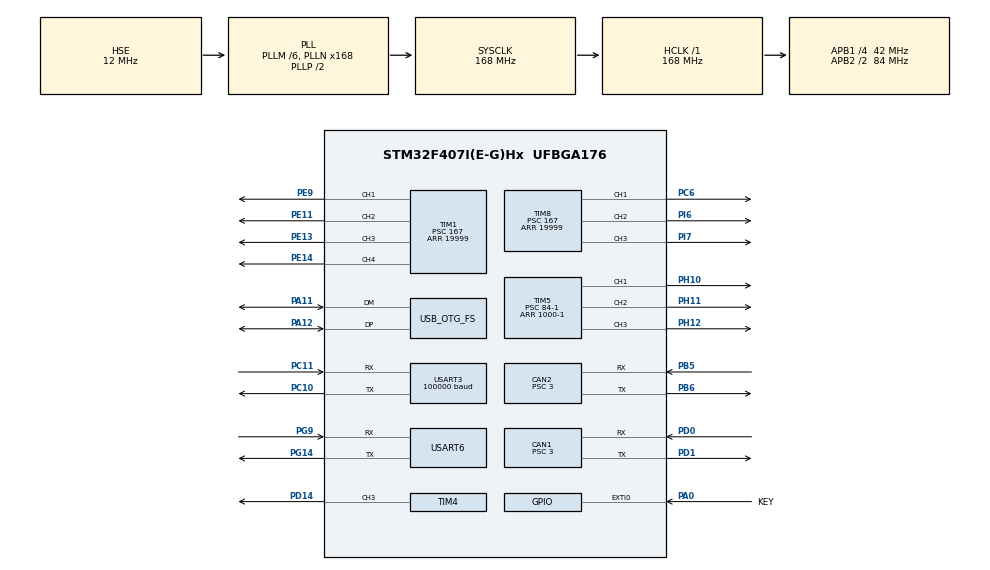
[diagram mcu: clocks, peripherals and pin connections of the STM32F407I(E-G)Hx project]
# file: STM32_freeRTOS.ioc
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CAN1.BS1=CAN_BS1_10TQ
CAN1.BS2=CAN_BS2_3TQ
CAN1.CalculateBaudRate=1000000
CAN1.CalculateTimeBit=1000
CAN1.CalculateTimeQuantum=71.42857142857143
CAN1.Prescaler=3
CAN2.BS1=CAN_BS1_10TQ
CAN2.BS2=CAN_BS2_3TQ
CAN2.CalculateBaudRate=1000000
CAN2.CalculateTimeBit=1000
CAN2.CalculateTimeQuantum=71.42857142857143
CAN2.Prescaler=3
Dma.Request0=USART3_RX
Dma.USART3_RX.0.Direction=DMA_PERIPH_TO_MEMORY
Dma.USART3_RX.0.FIFOMode=DMA_FIFOMODE_DISABLE
Dma.USART3_RX.0.Instance=DMA1_Stream1
Dma.USART3_RX.0.MemDataAlignment=DMA_MDATAALIGN_BYTE
Dma.USART3_RX.0.MemInc=DMA_MINC_ENABLE
Dma.USART3_RX.0.Mode=DMA_NORMAL
Dma.USART3_RX.0.PeriphDataAlignment=DMA_PDATAALIGN_BYTE
Dma.USART3_RX.0.PeriphInc=DMA_PINC_DISABLE
Dma.USART3_RX.0.Priority=DMA_PRIORITY_HIGH
FREERTOS.INCLUDE_eTaskGetState=1
FREERTOS.INCLUDE_pcTaskGetTaskName=1
FREERTOS.INCLUDE_vTaskCleanUpResources=1
FREERTOS.INCLUDE_vTaskDelayUntil=1
FREERTOS.INCLUDE_xQueueGetMutexHolder=1
FREERTOS.INCLUDE_xSemaphoreGetMutexHolder=1
FREERTOS.INCLUDE_xTaskAbortDelay=1
FREERTOS.INCLUDE_xTaskGetCurrentTaskHandle=1
FREERTOS.INCLUDE_xTaskGetHandle=1
FREERTOS.Tasks01=LED_RED,0,128,red_led_task,Default,NULL,Dynamic,NULL,NULL;LED_GREEN,0,128,green_led_task,As external,NULL,Dynamic,NULL,NULL;LED_BLUE,0,128,blue_led_task,As external,NULL,Dynamic,NULL,NULL
FREERTOS.configTOTAL_HEAP_SIZE=24576
Mcu.Family=STM32F4
Mcu.Name=STM32F407I(E-G)Hx
Mcu.Package=UFBGA176
NVIC.CAN1_RX0_IRQn=true\:5\:0\:false\:false\:true\:true\:true\:true\:true
NVIC.DMA1_Stream1_IRQn=true\:5\:0\:false\:false\:true\:true\:false\:true\:true
NVIC.EXTI0_IRQn=true\:5\:0\:false\:false\:true\:true\:true\:true\:true
NVIC.OTG_FS_IRQn=true\:5\:0\:false\:false\:true\:true\:false\:true\:true
NVIC.PriorityGroup=NVIC_PRIORITYGROUP_4
NVIC.TIM1_UP_TIM10_IRQn=true\:5\:0\:false\:false\:true\:true\:true\:true\:true
NVIC.USART3_IRQn=true\:5\:0\:false\:false\:true\:true\:true\:true\:true
NVIC.USART6_IRQn=true\:5\:0\:false\:false\:true\:true\:true\:true\:true
PA0-WKUP.GPIO_Label=KEY
PA0-WKUP.GPIO_ModeDefaultEXTI=GPIO_MODE_IT_RISING_FALLING
PA0-WKUP.GPIO_PuPd=GPIO_PULLUP
PA0-WKUP.Signal=GPXTI0
PA11.Mode=Device_Only
PA11.Signal=USB_OTG_FS_DM
PA12.Mode=Device_Only
PA12.Signal=USB_OTG_FS_DP
PA13.Mode=Serial_Wire
PA13.Signal=SYS_JTMS-SWDIO
PA14.Mode=Serial_Wire
PA14.Signal=SYS_JTCK-SWCLK
PB5.Mode=CAN_Activate
PB5.Signal=CAN2_RX
PB6.Mode=CAN_Activate
PB6.Signal=CAN2_TX
PC10.Mode=Asynchronous
PC10.Signal=USART3_TX
PC11.Mode=Asynchronous
PC11.Signal=USART3_RX
PC6.Signal=S_TIM8_CH1
PD0.Mode=CAN_Activate
PD0.Signal=CAN1_RX
PD1.Mode=CAN_Activate
PD1.Signal=CAN1_TX
PD14.Signal=S_TIM4_CH3
PE11.Signal=S_TIM1_CH2
PE13.Signal=S_TIM1_CH3
PE14.Signal=S_TIM1_CH4
PE9.Signal=S_TIM1_CH1
PG14.Mode=Asynchronous
PG14.Signal=USART6_TX
PG9.Mode=Asynchronous
PG9.Signal=USART6_RX
PH0-OSC_IN.Mode=HSE-External-Oscillator
PH0-OSC_IN.Signal=RCC_OSC_IN
PH1-OSC_OUT.Mode=HSE-External-Oscillator
PH1-OSC_OUT.Signal=RCC_OSC_OUT
PH10.GPIO_PuPd=GPIO_NOPULL
PH10.Signal=S_TIM5_CH1
PH11.GPIO_PuPd=GPIO_NOPULL
PH11.Signal=S_TIM5_CH2
PH12.GPIO_PuPd=GPIO_NOPULL
PH12.Signal=S_TIM5_CH3
PI6.Signal=S_TIM8_CH2
PI7.Signal=S_TIM8_CH3
ProjectManager.HeapSize=0x200
ProjectManager.StackSize=0x400
ProjectManager.TargetToolchain=STM32CubeIDE
RCC.48MHZClocksFreq_Value=48000000
RCC.AHBFreq_Value=168000000
RCC.APB1CLKDivider=RCC_HCLK_DIV4
RCC.APB1Freq_Value=42000000
RCC.APB1TimFreq_Value=84000000
RCC.APB2CLKDivider=RCC_HCLK_DIV2
RCC.APB2Freq_Value=84000000
RCC.APB2TimFreq_Value=168000000
RCC.CortexFreq_Value=168000000
RCC.EnbaleCSS=true
RCC.HCLKFreq_Value=168000000
RCC.HSE_VALUE=12000000
RCC.HSI_VALUE=16000000
RCC.LSE_VALUE=32768
RCC.PLLM=6
RCC.PLLN=168
RCC.PLLQ=7
RCC.SYSCLKFreq_VALUE=168000000
RCC.SYSCLKSource=RCC_SYSCLKSOURCE_PLLCLK
RCC.VCOOutputFreq_Value=336000000
SH.S_TIM1_CH1.0=TIM1_CH1,PWM Generation1 CH1
SH.S_TIM1_CH2.0=TIM1_CH2,PWM Generation2 CH2
SH.S_TIM1_CH3.0=TIM1_CH3,PWM Generation3 CH3
SH.S_TIM1_CH4.0=TIM1_CH4,PWM Generation4 CH4
SH.S_TIM4_CH3.0=TIM4_CH3,PWM Generation3 CH3
SH.S_TIM5_CH1.0=TIM5_CH1,PWM Generation1 CH1
SH.S_TIM5_CH2.0=TIM5_CH2,PWM Generation2 CH2
SH.S_TIM5_CH3.0=TIM5_CH3,PWM Generation3 CH3
SH.S_TIM8_CH1.0=TIM8_CH1,PWM Generation1 CH1
SH.S_TIM8_CH2.0=TIM8_CH2,PWM Generation2 CH2
SH.S_TIM8_CH3.0=TIM8_CH3,PWM Generation3 CH3
TIM1.Channel-PWM\ Generation1\ CH1=TIM_CHANNEL_1
TIM1.Channel-PWM\ Generation2\ CH2=TIM_CHANNEL_2
TIM1.Channel-PWM\ Generation3\ CH3=TIM_CHANNEL_3
TIM1.Channel-PWM\ Generation4\ CH4=TIM_CHANNEL_4
TIM1.Period=19999
TIM1.Prescaler=167
TIM1.Pulse-PWM\ Generation1\ CH1=5000
TIM1.Pulse-PWM\ Generation2\ CH2=2000
TIM1.Pulse-PWM\ Generation3\ CH3=2000
TIM1.Pulse-PWM\ Generation4\ CH4=2000
TIM4.Channel-PWM\ Generation3\ CH3=TIM_CHANNEL_3
TIM4.Period=1000-1
TIM4.Prescaler=1
TIM4.Pulse-PWM\ Generation3\ CH3=500
TIM5.Channel-PWM\ Generation1\ CH1=TIM_CHANNEL_1
TIM5.Channel-PWM\ Generation2\ CH2=TIM_CHANNEL_2
TIM5.Channel-PWM\ Generation3\ CH3=TIM_CHANNEL_3
TIM5.CounterMode=TIM_COUNTERMODE_UP
TIM5.OC1Preload_PWM=ENABLE
TIM5.Period=1000-1
TIM5.Prescaler=84-1
TIM5.Pulse-PWM\ Generation2\ CH2=0
TIM5.Pulse-PWM\ Generation3\ CH3=0
TIM8.Channel-PWM\ Generation1\ CH1=TIM_CHANNEL_1
TIM8.Channel-PWM\ Generation2\ CH2=TIM_CHANNEL_2
TIM8.Channel-PWM\ Generation3\ CH3=TIM_CHANNEL_3
TIM8.Period=19999
TIM8.Prescaler=167
TIM8.Pulse-PWM\ Generation1\ CH1=2000
TIM8.Pulse-PWM\ Generation2\ CH2=2000
TIM8.Pulse-PWM\ Generation3\ CH3=2000
USART3.BaudRate=100000
USART3.Parity=PARITY_EVEN
USART3.VirtualMode=VM_ASYNC
USART6.VirtualMode=VM_ASYNC
USB_DEVICE.CLASS_NAME_FS=CDC
USB_DEVICE.VirtualMode-CDC_FS=Cdc
USB_DEVICE.VirtualModeFS=Cdc_FS
USB_OTG_FS.VirtualMode=Device_Only
VP_CRC_VS_CRC.Mode=CRC_Activate
VP_FREERTOS_VS_CMSIS_V1.Mode=CMSIS_V1
VP_TIM1_VS_ClockSourceINT.Mode=Internal
VP_TIM4_VS_ClockSourceINT.Mode=Internal
VP_TIM5_VS_ClockSourceINT.Mode=Internal
VP_USB_DEVICE_VS_USB_DEVICE_CDC_FS.Mode=CDC_FS
board=custom

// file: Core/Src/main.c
/* USER CODE BEGIN Header */
/**
  ******************************************************************************
  * @file           : main.c
  * @brief          : Main program body
  ******************************************************************************
  * @attention
  *
  * Copyright (c) 2024 STMicroelectronics.
  * All rights reserved.
  *
  * This software is licensed under terms that can be found in the LICENSE file
  * in the root directory of this software component.
  * If no LICENSE file comes with this software, it is provided AS-IS.
  *
  ******************************************************************************
  */
/* USER CODE END Header */
#include "main.h"
#include "cmsis_os.h"
#include "can.h"
#include "crc.h"
#include "dma.h"
#include "tim.h"
#include "usart.h"
#include "usb_device.h"
#include "gpio.h"

void SystemClock_Config(void);
void MX_FREERTOS_Init(void);

int main(void)
{

  /* MCU Configuration--------------------------------------------------------*/

  /* Reset of all peripherals, Initializes the Flash interface and the Systick. */
  HAL_Init();

  /* Configure the system clock */
  SystemClock_Config();

  /* Initialize all configured peripherals */
  MX_GPIO_Init();
  MX_DMA_Init();
  MX_TIM5_Init();
  MX_TIM4_Init();
  MX_TIM8_Init();
  MX_TIM1_Init();
  MX_USART3_UART_Init();
  MX_USART6_UART_Init();
  MX_CAN1_Init();
  MX_CAN2_Init();
  MX_CRC_Init();
  /* USER CODE BEGIN 2 */
    HAL_TIM_Base_Start(&htim5);
    HAL_TIM_PWM_Start(&htim5,TIM_CHANNEL_1);
    HAL_TIM_PWM_Start(&htim5,TIM_CHANNEL_2);
    HAL_TIM_PWM_Start(&htim5,TIM_CHANNEL_3);
  /* USER CODE END 2 */

  /* Call init function for freertos objects (in freertos.c) */
  MX_FREERTOS_Init();

  /* Start scheduler */
  osKernelStart();

  /* We should never get here as control is now taken by the scheduler */
  /* Infinite loop */
  while (1)
  {

  }
}

void SystemClock_Config(void)
{
  RCC_OscInitTypeDef RCC_OscInitStruct = {0};
  RCC_ClkInitTypeDef RCC_ClkInitStruct = {0};

  /** Configure the main internal regulator output voltage
  */
  __HAL_RCC_PWR_CLK_ENABLE();
  __HAL_PWR_VOLTAGESCALING_CONFIG(PWR_REGULATOR_VOLTAGE_SCALE1);

  /** Initializes the RCC Oscillators according to the specified parameters
  * in the RCC_OscInitTypeDef structure.
  */
  RCC_OscInitStruct.OscillatorType = RCC_OSCILLATORTYPE_HSE;
  RCC_OscInitStruct.HSEState = RCC_HSE_ON;
  RCC_OscInitStruct.PLL.PLLState = RCC_PLL_ON;
  RCC_OscInitStruct.PLL.PLLSource = RCC_PLLSOURCE_HSE;
  RCC_OscInitStruct.PLL.PLLM = 6;
  RCC_OscInitStruct.PLL.PLLN = 168;
  RCC_OscInitStruct.PLL.PLLP = RCC_PLLP_DIV2;
  RCC_OscInitStruct.PLL.PLLQ = 7;
  if (HAL_RCC_OscConfig(&RCC_OscInitStruct) != HAL_OK)
  {
    Error_Handler();
  }

  /** Initializes the CPU, AHB and APB buses clocks
  */
  RCC_ClkInitStruct.ClockType = RCC_CLOCKTYPE_HCLK|RCC_CLOCKTYPE_SYSCLK
                              |RCC_CLOCKTYPE_PCLK1|RCC_CLOCKTYPE_PCLK2;
  RCC_ClkInitStruct.SYSCLKSource = RCC_SYSCLKSOURCE_PLLCLK;
  RCC_ClkInitStruct.AHBCLKDivider = RCC_SYSCLK_DIV1;
  RCC_ClkInitStruct.APB1CLKDivider = RCC_HCLK_DIV4;
  RCC_ClkInitStruct.APB2CLKDivider = RCC_HCLK_DIV2;

  if (HAL_RCC_ClockConfig(&RCC_ClkInitStruct, FLASH_LATENCY_5) != HAL_OK)
  {
    Error_Handler();
  }

  /** Enables the Clock Security System
  */
  HAL_RCC_EnableCSS();
}

void Error_Handler(void)
{
  __disable_irq();
  while (1)
  {
  }
}

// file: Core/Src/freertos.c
/* USER CODE BEGIN Header */
/**
  ******************************************************************************
  * File Name          : freertos.c
  * Description        : Code for freertos applications
  ******************************************************************************
  * @attention
  *
  * Copyright (c) 2024 STMicroelectronics.
  * All rights reserved.
  *
  * This software is licensed under terms that can be found in the LICENSE file
  * in the root directory of this software component.
  * If no LICENSE file comes with this software, it is provided AS-IS.
  *
  ******************************************************************************
  */
/* USER CODE END Header */

#include "FreeRTOS.h"
#include "task.h"
#include "main.h"
#include "cmsis_os.h"

/* USER CODE BEGIN Variables */
osThreadId usb_task_handle;
osThreadId decode_task_handle;
/* USER CODE END Variables */
osThreadId LED_REDHandle;
osThreadId LED_GREENHandle;
osThreadId LED_BLUEHandle;

void red_led_task(void const * argument);
extern void green_led_task(void const * argument);
extern void blue_led_task(void const * argument);

extern void MX_USB_DEVICE_Init(void);
void MX_FREERTOS_Init(void); /* (MISRA C 2004 rule 8.1) */

/* GetIdleTaskMemory prototype (linked to static allocation support) */
void vApplicationGetIdleTaskMemory( StaticTask_t **ppxIdleTaskTCBBuffer, StackType_t **ppxIdleTaskStackBuffer, uint32_t *pulIdleTaskStackSize );

/* USER CODE BEGIN GET_IDLE_TASK_MEMORY */
static StaticTask_t xIdleTaskTCBBuffer;
static StackType_t xIdleStack[configMINIMAL_STACK_SIZE];

void vApplicationGetIdleTaskMemory( StaticTask_t **ppxIdleTaskTCBBuffer, StackType_t **ppxIdleTaskStackBuffer, uint32_t *pulIdleTaskStackSize )
{
  *ppxIdleTaskTCBBuffer = &xIdleTaskTCBBuffer;
  *ppxIdleTaskStackBuffer = &xIdleStack[0];
  *pulIdleTaskStackSize = configMINIMAL_STACK_SIZE;
  /* place for user code */
}
// USB数据队列
QueueHandle_t CDC_send_queue;
_Noreturn extern void usb_task(void const * argument);
extern void decode_task(void const * argument);
/* USER CODE END GET_IDLE_TASK_MEMORY */

void MX_FREERTOS_Init(void) {

  /* Create the thread(s) */
  /* definition and creation of LED_RED */
  osThreadDef(LED_RED, red_led_task, osPriorityNormal, 0, 128);
  LED_REDHandle = osThreadCreate(osThread(LED_RED), NULL);

  /* definition and creation of LED_GREEN */
  osThreadDef(LED_GREEN, green_led_task, osPriorityNormal, 0, 128);
  LED_GREENHandle = osThreadCreate(osThread(LED_GREEN), NULL);

  /* definition and creation of LED_BLUE */
  osThreadDef(LED_BLUE, blue_led_task, osPriorityNormal, 0, 128);
  LED_BLUEHandle = osThreadCreate(osThread(LED_BLUE), NULL);

  /* USER CODE BEGIN RTOS_THREADS */
  /* add threads, ... */
    // USB发送数据任务
    osThreadDef(USB_task,usb_task,osPriorityHigh,0,128);
    usb_task_handle= osThreadCreate(osThread(USB_task),NULL);
    // USB接收解码任务
    osThreadDef(DecodeTask, decode_task, osPriorityHigh, 0, 128);
    decode_task_handle = osThreadCreate(osThread(DecodeTask), NULL);
    // 创建队列
    CDC_send_queue = xQueueCreate(1, 128);
  /* USER CODE END RTOS_THREADS */

}

void red_led_task(void const * argument)
{
  /* init code for USB_DEVICE */
  MX_USB_DEVICE_Init();
  for(;;)
  {
    osDelay(1);
  }
}

/* USER CODE BEGIN Application */

void blue_led_task(void const * argument){
    vTaskDelete(NULL);
}

/* USER CODE END Application */
